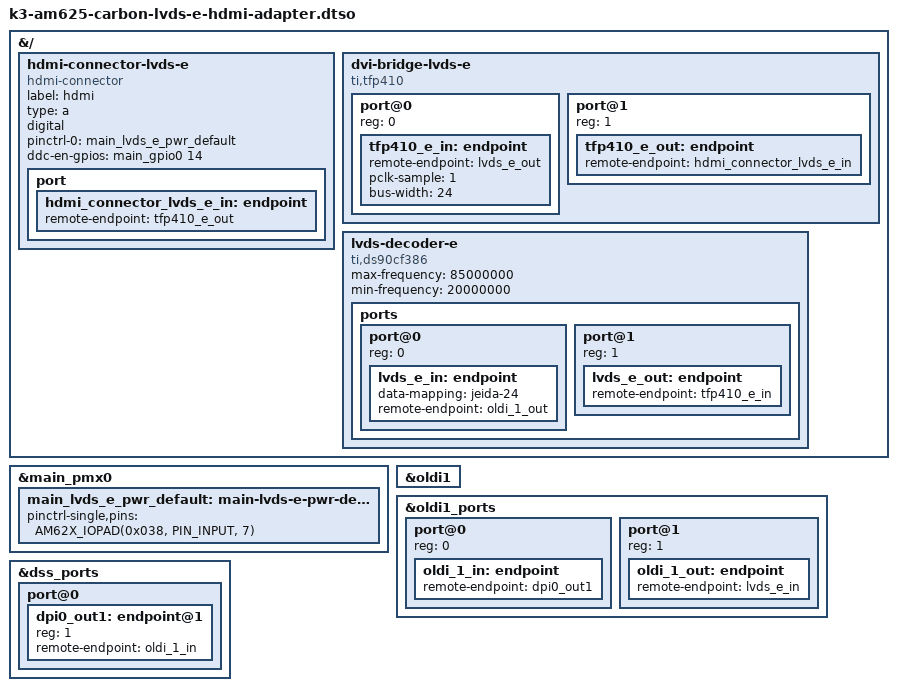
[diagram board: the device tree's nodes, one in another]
// SPDX-License-Identifier: GPL-2.0-only OR MIT
/*
 * LVDS E to HDMI Expansion Board for Carbon AM62xx
 *
 * Copyright (C) 2024 Ezurio LLC
 */

/dts-v1/;
/plugin/;

#include <dt-bindings/gpio/gpio.h>
#include "ti/k3-pinctrl.h"

/* CAUTION: LVDS E channel on AM62x is the companion channel to the LVDS D 
   it will work only when LVDS D is active and will function as the mirror
   or potentially dual-link LVDS which is not suppoted here

   The device tree provides only additions needed to LVDS D
 */

&{/} {
	hdmi-connector-lvds-e {
		compatible = "hdmi-connector";
		label = "hdmi";
		type = "a";
		digital;

		pinctrl-names = "default";
		pinctrl-0 = <&main_lvds_e_pwr_default>;
		ddc-en-gpios = <&main_gpio0 14 GPIO_ACTIVE_HIGH>;

		port {
			hdmi_connector_lvds_e_in: endpoint {
				remote-endpoint = <&tfp410_e_out>;
			};
		};
	};

	dvi-bridge-lvds-e {
		#address-cells = <1>;
		#size-cells = <0>;
		compatible = "ti,tfp410";

		//pinctrl-names = "default";
		//pinctrl-0 = <&main_lvds_e_pwr_default>;
		//powerdown-gpios = <&main_gpio0 14 GPIO_ACTIVE_HIGH>;

		port@0 {
			reg = <0>;
			tfp410_e_in: endpoint {
				remote-endpoint = <&lvds_e_out>;
				pclk-sample = <1>;
				bus-width = <24>;
			};
		};

		port@1 {
			reg = <1>;
			tfp410_e_out: endpoint {
				remote-endpoint = <&hdmi_connector_lvds_e_in>;
			};
		};
	};

	lvds-decoder-e {
		compatible = "ti,ds90cf386", "lvds-decoder";

		max-frequency = <85000000>;
		min-frequency = <20000000>;

		ports {
			#address-cells = <1>;
			#size-cells = <0>;

			port@0 {
				reg = <0>;
				lvds_e_in: endpoint {
					data-mapping = "jeida-24";
					remote-endpoint = <&oldi_1_out>;
				};
			};

			port@1 {
				reg = <1>;
				lvds_e_out: endpoint {
					remote-endpoint = <&tfp410_e_in>;
				};
			};
		};
	};
};

&main_pmx0 {
	/* CAUTION: LVDS_E_VDD_EN is shared with RGB_VDD_EN 
	   as such these functions cannot be used together */
	main_lvds_e_pwr_default: main-lvds-e-pwr-default-pins {
		pinctrl-single,pins = <
			AM62X_IOPAD(0x038, PIN_INPUT, 7) /* LVDS_E_VDD_EN (E24) OSPI0_CSn3.GPIO0_14 */
		>;
	};
};

&oldi1 {
	status = "okay";
};

&oldi1_ports {
	#address-cells = <1>;
	#size-cells = <0>;

	port@0 {
		reg = <0>;
		oldi_1_in: endpoint {
			remote-endpoint = <&dpi0_out1>;
		};
	};

	port@1 {
		reg = <1>;
		oldi_1_out: endpoint {
			remote-endpoint = <&lvds_e_in>;
		};
	};
};

&dss_ports {
	/* Video Port 1 Output to OLDI */
	port@0 {
		#address-cells = <1>;
		#size-cells = <0>;

		dpi0_out1: endpoint@1 {
			reg = <1>;
			remote-endpoint = <&oldi_1_in>;
		};
	};
};
